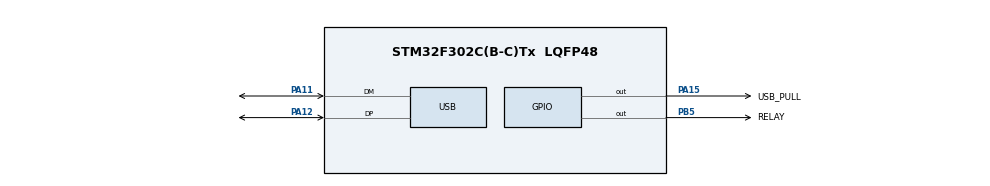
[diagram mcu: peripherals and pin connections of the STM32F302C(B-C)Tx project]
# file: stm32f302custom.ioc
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FREERTOS.HEAP_NUMBER=1
FREERTOS.Tasks01=defaultTask,24,128,StartDefaultTask,Default,NULL,Dynamic,NULL,NULL
Mcu.Family=STM32F3
Mcu.Name=STM32F302C(B-C)Tx
Mcu.Package=LQFP48
NVIC.PriorityGroup=NVIC_PRIORITYGROUP_4
NVIC.TIM1_UP_TIM16_IRQn=true\:15\:0\:false\:false\:true\:false\:false\:true
NVIC.TimeBase=TIM1_UP_TIM16_IRQn
NVIC.TimeBaseIP=TIM1
NVIC.USB_LP_CAN_RX0_IRQn=true\:5\:0\:false\:false\:true\:true\:false\:true
PA11.Mode=Device
PA11.Signal=USB_DM
PA12.Mode=Device
PA12.Signal=USB_DP
PA13.Mode=Serial_Wire
PA13.Signal=SYS_JTMS-SWDIO
PA14.Mode=Serial_Wire
PA14.Signal=SYS_JTCK-SWCLK
PA15.GPIO_Label=USB_PULL
PA15.PinState=GPIO_PIN_SET
PA15.Signal=GPIO_Output
PB5.GPIO_Label=RELAY
PB5.GPIO_Speed=GPIO_SPEED_FREQ_LOW
PB5.PinState=GPIO_PIN_RESET
PB5.Signal=GPIO_Output
PF0-OSC_IN.Mode=HSE-External-Oscillator
PF0-OSC_IN.Signal=RCC_OSC_IN
PF1-OSC_OUT.Mode=HSE-External-Oscillator
PF1-OSC_OUT.Signal=RCC_OSC_OUT
ProjectManager.HeapSize=0x200
ProjectManager.StackSize=0x400
ProjectManager.TargetToolchain=STM32CubeIDE
RCC.AHBFreq_Value=72000000
RCC.APB1CLKDivider=RCC_HCLK_DIV2
RCC.APB1Freq_Value=36000000
RCC.APB1TimFreq_Value=72000000
RCC.APB2Freq_Value=72000000
RCC.APB2TimFreq_Value=72000000
RCC.CortexFreq_Value=72000000
RCC.HCLKFreq_Value=72000000
RCC.HSE_VALUE=8000000
RCC.HSI_VALUE=8000000
RCC.LSE_VALUE=32768
RCC.PLLMUL=RCC_PLL_MUL9
RCC.PRESCALERUSB=RCC_USBCLKSOURCE_PLL_DIV1_5
RCC.SYSCLKFreq_VALUE=72000000
RCC.SYSCLKSourceVirtual=RCC_SYSCLKSOURCE_PLLCLK
RCC.USBFreq_Value=48000000
USB_DEVICE.CLASS_NAME_FS=CDC
USB_DEVICE.VirtualMode=Cdc
USB_DEVICE.VirtualModeFS=Cdc_FS
VP_FREERTOS_VS_CMSIS_V2.Mode=CMSIS_V2
VP_SYS_VS_tim1.Mode=TIM1
VP_USB_DEVICE_VS_USB_DEVICE_CDC_FS.Mode=CDC_FS
board=custom

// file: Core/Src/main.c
/* USER CODE BEGIN Header */
/**
  ******************************************************************************
  * @file           : main.c
  * @brief          : Main program body
  ******************************************************************************
  * @attention
  *
  * <h2><center>&copy; Copyright (c) 2020 STMicroelectronics.
  * All rights reserved.</center></h2>
  *
  * This software component is licensed by ST under Ultimate Liberty license
  * SLA0044, the "License"; You may not use this file except in compliance with
  * the License. You may obtain a copy of the License at:
  *                             www.st.com/SLA0044
  *
  ******************************************************************************
  */
/* USER CODE END Header */
#include "main.h"
#include "cmsis_os.h"
#include "usb_device.h"

/* USER CODE BEGIN Includes */
#include "app_cli.h"
/* USER CODE END Includes */

/* Definitions for defaultTask */
osThreadId_t defaultTaskHandle;
const osThreadAttr_t defaultTask_attributes = {
  .name = "defaultTask",
  .stack_size = 128 * 4,
  .priority = (osPriority_t) osPriorityNormal,
};

void SystemClock_Config(void);
static void MX_GPIO_Init(void);
void StartDefaultTask(void *argument);

int main(void)
{

  /* MCU Configuration--------------------------------------------------------*/

  /* Reset of all peripherals, Initializes the Flash interface and the Systick. */
  HAL_Init();

  /* Configure the system clock */
  SystemClock_Config();

  /* Initialize all configured peripherals */
  MX_GPIO_Init();

  /* Init scheduler */
  osKernelInitialize();

  /* Create the thread(s) */
  /* creation of defaultTask */
  defaultTaskHandle = osThreadNew(StartDefaultTask, NULL, &defaultTask_attributes);

  /* Start scheduler */
  osKernelStart();

  /* We should never get here as control is now taken by the scheduler */
  /* Infinite loop */
  while (1)
  {

  }
}

void SystemClock_Config(void)
{
  LL_FLASH_SetLatency(LL_FLASH_LATENCY_2);
  while(LL_FLASH_GetLatency()!= LL_FLASH_LATENCY_2)
  {
  }
  LL_RCC_HSE_Enable();

   /* Wait till HSE is ready */
  while(LL_RCC_HSE_IsReady() != 1)
  {

  }
  LL_RCC_PLL_ConfigDomain_SYS(LL_RCC_PLLSOURCE_HSE_DIV_1, LL_RCC_PLL_MUL_9);
  LL_RCC_PLL_Enable();

   /* Wait till PLL is ready */
  while(LL_RCC_PLL_IsReady() != 1)
  {

  }
  LL_RCC_SetAHBPrescaler(LL_RCC_SYSCLK_DIV_1);
  LL_RCC_SetAPB1Prescaler(LL_RCC_APB1_DIV_2);
  LL_RCC_SetAPB2Prescaler(LL_RCC_APB2_DIV_1);
  LL_RCC_SetSysClkSource(LL_RCC_SYS_CLKSOURCE_PLL);

   /* Wait till System clock is ready */
  while(LL_RCC_GetSysClkSource() != LL_RCC_SYS_CLKSOURCE_STATUS_PLL)
  {

  }
  LL_SetSystemCoreClock(72000000);

   /* Update the time base */
  if (HAL_InitTick (TICK_INT_PRIORITY) != HAL_OK)
  {
    Error_Handler();
  }
  LL_RCC_SetUSBClockSource(LL_RCC_USB_CLKSOURCE_PLL_DIV_1_5);
}

static void MX_GPIO_Init(void)
{
  LL_GPIO_InitTypeDef GPIO_InitStruct = {0};

  /* GPIO Ports Clock Enable */
  LL_AHB1_GRP1_EnableClock(LL_AHB1_GRP1_PERIPH_GPIOF);
  LL_AHB1_GRP1_EnableClock(LL_AHB1_GRP1_PERIPH_GPIOA);
  LL_AHB1_GRP1_EnableClock(LL_AHB1_GRP1_PERIPH_GPIOB);

  /**/
  LL_GPIO_SetOutputPin(USB_PULL_GPIO_Port, USB_PULL_Pin);

  /**/
  LL_GPIO_ResetOutputPin(RELAY_GPIO_Port, RELAY_Pin);

  /**/
  GPIO_InitStruct.Pin = USB_PULL_Pin;
  GPIO_InitStruct.Mode = LL_GPIO_MODE_OUTPUT;
  GPIO_InitStruct.Speed = LL_GPIO_SPEED_FREQ_LOW;
  GPIO_InitStruct.OutputType = LL_GPIO_OUTPUT_PUSHPULL;
  GPIO_InitStruct.Pull = LL_GPIO_PULL_NO;
  LL_GPIO_Init(USB_PULL_GPIO_Port, &GPIO_InitStruct);

  /**/
  GPIO_InitStruct.Pin = RELAY_Pin;
  GPIO_InitStruct.Mode = LL_GPIO_MODE_OUTPUT;
  GPIO_InitStruct.Speed = LL_GPIO_SPEED_FREQ_LOW;
  GPIO_InitStruct.OutputType = LL_GPIO_OUTPUT_PUSHPULL;
  GPIO_InitStruct.Pull = LL_GPIO_PULL_NO;
  LL_GPIO_Init(RELAY_GPIO_Port, &GPIO_InitStruct);

}

void StartDefaultTask(void *argument)
{
  /* init code for USB_DEVICE */
  MX_USB_DEVICE_Init();
  /* USER CODE BEGIN 5 */
  APP_cli_init();
  /* Infinite loop */
  for(;;)
  {
    osDelay(1);
  }
  /* USER CODE END 5 */
}

void HAL_TIM_PeriodElapsedCallback(TIM_HandleTypeDef *htim)
{
  if (htim->Instance == TIM1) {
    HAL_IncTick();
  }
}

void Error_Handler(void)
{
}
